VERSION "0.1"

NS_ :

BS_: 1000000

BU_: PC X

BO_ 2147483906 SetDeviceId: 4 Vector__XXX
    SG_ id : 0|32@1+ (1,0) [0|0] "" Vector__XXX

BO_ 2147484162 SetCanBitrate: 1 Vector__XXX
    SG_ can_bitrate : 0|8@1+ (1,0) [0|0] "" Vector__XXX

BO_ 2148531970 GetProductInfo: 0 Vector__XXX

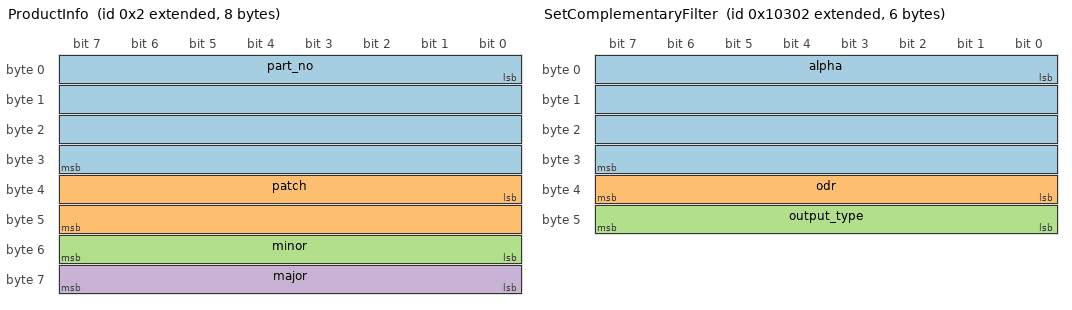
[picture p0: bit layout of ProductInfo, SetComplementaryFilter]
BO_ 2147483650 ProductInfo: 8 Vector__XXX
    SG_ part_no : 0|32@1+ (1,0) [0|0] "" Vector__XXX
    SG_ patch : 32|16@1+ (1,0) [0|0] "" Vector__XXX
    SG_ minor : 48|8@1+ (1,0) [0|0] "" Vector__XXX
    SG_ major : 56|8@1+ (1,0) [0|0] "" Vector__XXX

BO_ 2148073474 Status: 1 Vector__XXX
    SG_ status : 0|8@1+ (1,0) [0|0] "" Vector__XXX

BO_ 2148073730 ClearStatus: 0 Vector__XXX

BO_ 2147484418 WriteToFlash: 0 Vector__XXX

BO_ 2148077570 Ack: 4 Vector__XXX
    SG_ ident : 0|32@1+ (1,0) [0|0] "" Vector__XXX

BO_ 2148074242 Nack: 1 Vector__XXX
    SG_ status : 0|8@1+ (1,0) [0|0] "" Vector__XXX

BO_ 2148112386 SoftReset: 0 Vector__XXX

BO_ 2148112642 Reboot: 0 Vector__XXX

BO_ 2148073986 SetStatusRate: 1 Vector__XXX
    SG_ status_rate : 0|8@1+ (1,0) [0|0] "" Vector__XXX

BO_ 2147549442 ScalingFactors: 8 Vector__XXX
    SG_ accel_scale : 0|32@1+ (1,0) [0|0] "" Vector__XXX
    SG_ gyro_scale : 32|32@1+ (1,0) [0|0] "" Vector__XXX

BO_ 2147549698 DoGyroCalibration: 0 Vector__XXX

BO_ 2147549954 SetComplementaryFilter: 6 Vector__XXX
    SG_ alpha : 0|32@1+ (1,0) [0|0] "" Vector__XXX
    SG_ odr : 32|8@1+ (1,0) [0|0] "" Vector__XXX
    SG_ output_type : 40|8@1+ (1,0) [0|0] "" Vector__XXX

BO_ 2147550210 SetAccelFilter: 2 Vector__XXX
    SG_ odr_div : 0|8@1+ (1,0) [0|0] "" Vector__XXX
    SG_ lp_div : 8|8@1+ (1,0) [0|0] "" Vector__XXX

BO_ 2147550466 SetGyroFilter: 2 Vector__XXX
    SG_ odr_div : 0|8@1+ (1,0) [0|0] "" Vector__XXX
    SG_ lp_div : 8|8@1+ (1,0) [0|0] "" Vector__XXX

BO_ 2147550722 SetAccelResolution: 1 Vector__XXX
    SG_ full_scale : 0|8@1+ (1,0) [0|0] "" Vector__XXX

BO_ 2147550978 SetGyroResolution: 1 Vector__XXX
    SG_ full_scale : 0|8@1+ (1,0) [0|0] "" Vector__XXX

BO_ 2147551234 SetDeviceOrientation: 8 Vector__XXX
    SG_ pitch : 0|32@1+ (1,0) [0|0] "degrees" Vector__XXX
    SG_ roll : 32|32@1+ (1,0) [0|0] "degrees" Vector__XXX

BO_ 2147746050 DeviceId: 1 Vector__XXX
    SG_ id : 0|8@1+ (1,0) [0|0] "" Vector__XXX

BO_ 2147746306 GyroFilter: 2 Vector__XXX
    SG_ odr_div : 0|8@1+ (1,0) [0|0] "" Vector__XXX
    SG_ lp_div : 8|8@1+ (1,0) [0|0] "" Vector__XXX

BO_ 2147746562 AccelFilter: 2 Vector__XXX
    SG_ odr_div : 0|8@1+ (1,0) [0|0] "" Vector__XXX
    SG_ lp_div : 8|8@1+ (1,0) [0|0] "" Vector__XXX

BO_ 2147746818 AccelResolution: 1 Vector__XXX
    SG_ full_scale : 0|8@1+ (1,0) [0|0] "" Vector__XXX

BO_ 2147747074 GyroResolution: 1 Vector__XXX
    SG_ full_scale : 0|8@1+ (1,0) [0|0] "" Vector__XXX

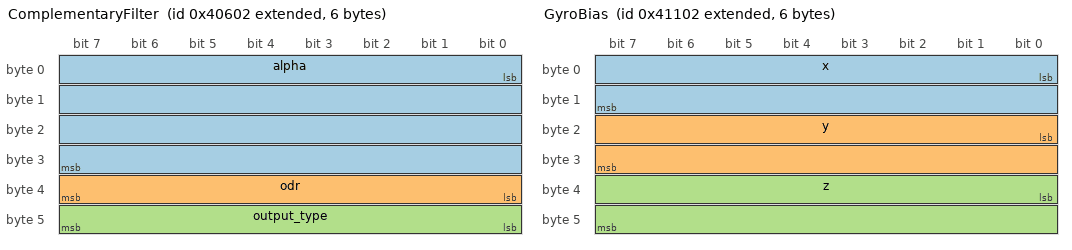
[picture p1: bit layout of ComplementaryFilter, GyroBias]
BO_ 2147747330 ComplementaryFilter: 6 Vector__XXX
    SG_ alpha : 0|32@1+ (1,0) [0|0] "" Vector__XXX
    SG_ odr : 32|8@1+ (1,0) [0|0] "" Vector__XXX
    SG_ output_type : 40|8@1+ (1,0) [0|0] "" Vector__XXX

BO_ 2147747586 GetScalingFactors: 0 Vector__XXX

BO_ 2147747842 GetConfig: 0 Vector__XXX

BO_ 2147748098 GetSensorFreqFine: 0 Vector__XXX

BO_ 2147749890 SensorFreqFine: 4 Vector__XXX
    SG_ fine : 0|32@1+ (1,0) [0|0] "" Vector__XXX

BO_ 2147750146 GyroBias: 6 Vector__XXX
    SG_ x : 0|16@1- (1,0) [0|0] "" Vector__XXX
    SG_ y : 16|16@1- (1,0) [0|0] "" Vector__XXX
    SG_ z : 32|16@1- (1,0) [0|0] "" Vector__XXX

BO_ 2147750402 CanSpeed: 1 Vector__XXX
    SG_ can_bitrate : 0|8@1+ (1,0) [0|0] "" Vector__XXX

BO_ 2147750658 DeviceOrientation: 8 Vector__XXX
    SG_ pitch : 0|32@1+ (1,0) [0|0] "degrees" Vector__XXX
    SG_ roll : 32|32@1+ (1,0) [0|0] "degrees" Vector__XXX

BO_ 2147750914 StatusRate: 1 Vector__XXX
    SG_ status_rate : 0|8@1+ (1,0) [0|0] "" Vector__XXX

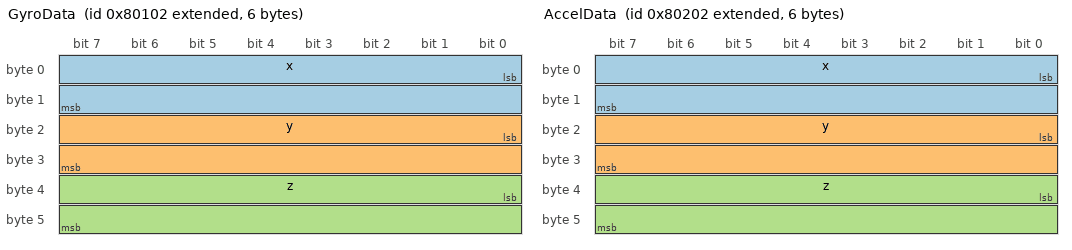
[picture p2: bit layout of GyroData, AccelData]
BO_ 2148008194 GyroData: 6 Vector__XXX
    SG_ x : 0|16@1- (1,0) [0|0] "" Vector__XXX
    SG_ y : 16|16@1- (1,0) [0|0] "" Vector__XXX
    SG_ z : 32|16@1- (1,0) [0|0] "" Vector__XXX

BO_ 2148008450 AccelData: 6 Vector__XXX
    SG_ x : 0|16@1- (1,0) [0|0] "" Vector__XXX
    SG_ y : 16|16@1- (1,0) [0|0] "" Vector__XXX
    SG_ z : 32|16@1- (1,0) [0|0] "" Vector__XXX

BO_ 2148008706 TiltAngles: 8 Vector__XXX
    SG_ pitch : 0|32@1+ (1,0) [0|0] "degrees" Vector__XXX
    SG_ roll : 32|32@1+ (1,0) [0|0] "degrees" Vector__XXX

BO_ 2148008962 QuatWX: 8 Vector__XXX
    SG_ w : 0|32@1+ (1,0) [0|0] "" Vector__XXX
    SG_ x : 32|32@1+ (1,0) [0|0] "" Vector__XXX

BO_ 2148009218 QuatYZ: 8 Vector__XXX
    SG_ y : 0|32@1+ (1,0) [0|0] "" Vector__XXX
    SG_ z : 32|32@1+ (1,0) [0|0] "" Vector__XXX

BA_DEF_DEF_ "BusType" "CAN";

SIG_VALTYPE_ 2147549442 accel_scale : 1;
SIG_VALTYPE_ 2147549442 gyro_scale : 1;
SIG_VALTYPE_ 2147549954 alpha : 1;
SIG_VALTYPE_ 2147551234 pitch : 1;
SIG_VALTYPE_ 2147551234 roll : 1;
SIG_VALTYPE_ 2147747330 alpha : 1;
SIG_VALTYPE_ 2147750658 pitch : 1;
SIG_VALTYPE_ 2147750658 roll : 1;
SIG_VALTYPE_ 2148008706 pitch : 1;
SIG_VALTYPE_ 2148008706 roll : 1;
SIG_VALTYPE_ 2148008962 w : 1;
SIG_VALTYPE_ 2148008962 x : 1;
SIG_VALTYPE_ 2148008962 y : 1;
SIG_VALTYPE_ 2148008962 z : 1;
